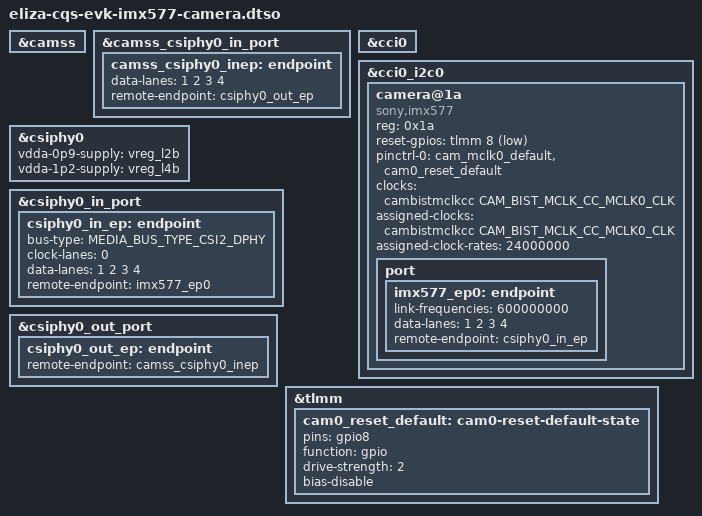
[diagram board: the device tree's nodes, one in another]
// SPDX-License-Identifier: BSD-3-Clause
/*
 * Copyright (c) Qualcomm Technologies, Inc. and/or its subsidiaries.
 */

/dts-v1/;
/plugin/;

#include <dt-bindings/clock/qcom,eliza-cambistmclkcc.h>
#include <dt-bindings/gpio/gpio.h>
#include <dt-bindings/media/video-interfaces.h>

&camss {
	status = "okay";
};

&camss_csiphy0_in_port {
	camss_csiphy0_inep: endpoint {
		data-lanes = <1 2 3 4>;
		remote-endpoint = <&csiphy0_out_ep>;
	};
};

&cci0 {
	status = "okay";
};

&cci0_i2c0 {
	camera@1a {
		compatible = "sony,imx577";
		reg = <0x1a>;

		reset-gpios = <&tlmm 8 GPIO_ACTIVE_LOW>;
		pinctrl-0 = <&cam_mclk0_default &cam0_reset_default>;
		pinctrl-names = "default";

		clocks = <&cambistmclkcc CAM_BIST_MCLK_CC_MCLK0_CLK>;
		assigned-clocks = <&cambistmclkcc CAM_BIST_MCLK_CC_MCLK0_CLK>;
		assigned-clock-rates = <24000000>;

		port {
			imx577_ep0: endpoint {
				link-frequencies = /bits/ 64 <600000000>;
				data-lanes = <1 2 3 4>;
				remote-endpoint = <&csiphy0_in_ep>;
			};
		};
	};
};

&csiphy0 {
	vdda-0p9-supply = <&vreg_l2b>;
	vdda-1p2-supply = <&vreg_l4b>;

	status = "okay";
};

&csiphy0_in_port {
	csiphy0_in_ep: endpoint {
		bus-type = <MEDIA_BUS_TYPE_CSI2_DPHY>;
		clock-lanes = <0>;
		data-lanes = <1 2 3 4>;
		remote-endpoint = <&imx577_ep0>;
	};
};

&csiphy0_out_port {
	csiphy0_out_ep: endpoint {
		remote-endpoint = <&camss_csiphy0_inep>;
	};
};

&tlmm {
	cam0_reset_default: cam0-reset-default-state {
		pins = "gpio8";
		function = "gpio";
		drive-strength = <2>;
		bias-disable;
	};
};
